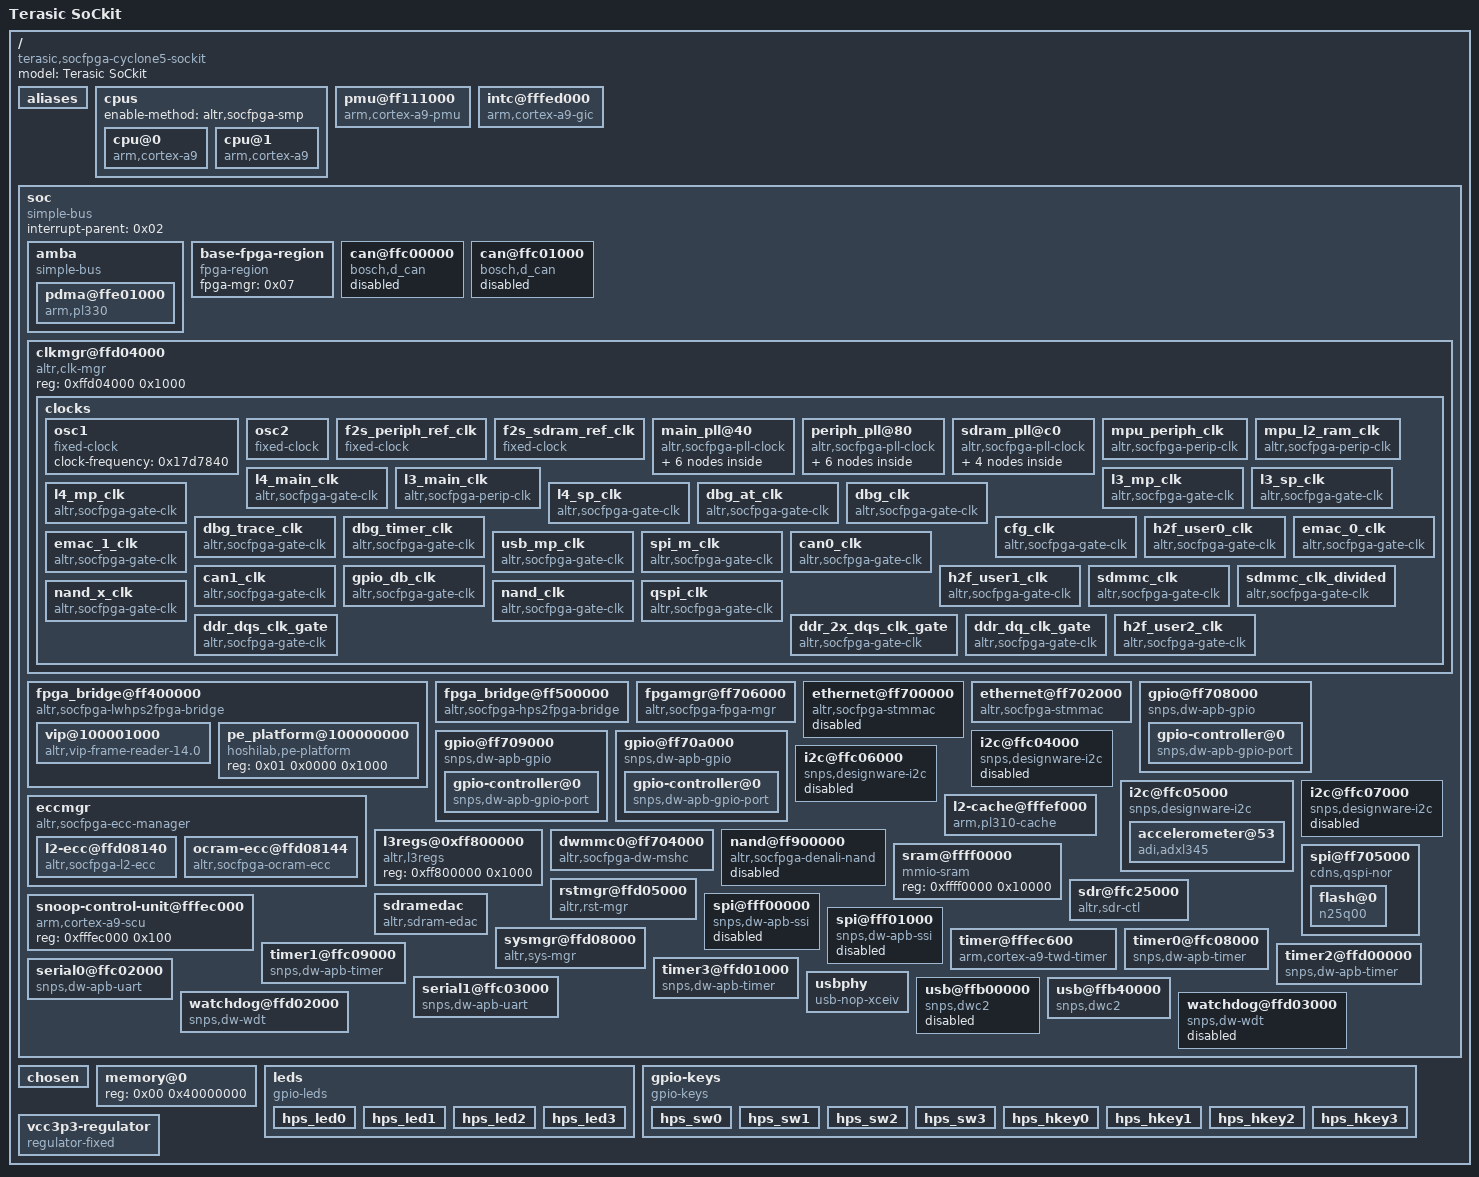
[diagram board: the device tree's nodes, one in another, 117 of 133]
/dts-v1/;

/memreserve/	0x0000000000000000 0x0000000000001000;
/ {
	#address-cells = < 0x01 >;
	#size-cells = < 0x01 >;
	model = "Terasic SoCkit";
	compatible = "terasic,socfpga-cyclone5-sockit\0altr,socfpga-cyclone5\0altr,socfpga";

	aliases {
		ethernet0 = "/soc/ethernet@ff702000";
		ethernet1 = "/soc/ethernet@ff702000";
		serial0 = "/soc/serial0@ffc02000";
		serial1 = "/soc/serial1@ffc03000";
		timer0 = "/soc/timer0@ffc08000";
		timer1 = "/soc/timer1@ffc09000";
		timer2 = "/soc/timer2@ffd00000";
		timer3 = "/soc/timer3@ffd01000";
	};

	cpus {
		#address-cells = < 0x01 >;
		#size-cells = < 0x00 >;
		enable-method = "altr,socfpga-smp";

		cpu@0 {
			compatible = "arm,cortex-a9";
			device_type = "cpu";
			reg = < 0x00 >;
			next-level-cache = < 0x01 >;
			linux,phandle = < 0x03 >;
			phandle = < 0x03 >;
		};

		cpu@1 {
			compatible = "arm,cortex-a9";
			device_type = "cpu";
			reg = < 0x01 >;
			next-level-cache = < 0x01 >;
			linux,phandle = < 0x04 >;
			phandle = < 0x04 >;
		};
	};

	pmu@ff111000 {
		compatible = "arm,cortex-a9-pmu";
		interrupt-parent = < 0x02 >;
		interrupts = < 0x00 0xb0 0x04 0x00 0xb1 0x04 >;
		interrupt-affinity = < 0x03 0x04 >;
		reg = < 0xff111000 0x1000 0xff113000 0x1000 >;
		linux,phandle = < 0x36 >;
		phandle = < 0x36 >;
	};

	intc@fffed000 {
		compatible = "arm,cortex-a9-gic";
		#interrupt-cells = < 0x03 >;
		interrupt-controller;
		reg = < 0xfffed000 0x1000 0xfffec100 0x100 >;
		linux,phandle = < 0x02 >;
		phandle = < 0x02 >;
	};

	soc {
		#address-cells = < 0x01 >;
		#size-cells = < 0x01 >;
		compatible = "simple-bus";
		device_type = "soc";
		interrupt-parent = < 0x02 >;
		ranges;

		amba {
			compatible = "simple-bus";
			#address-cells = < 0x01 >;
			#size-cells = < 0x01 >;
			ranges;

			pdma@ffe01000 {
				compatible = "arm,pl330\0arm,primecell";
				reg = < 0xffe01000 0x1000 >;
				interrupts = < 0x00 0x68 0x04 0x00 0x69 0x04 0x00 0x6a 0x04 0x00 0x6b 0x04 0x00 0x6c 0x04 0x00 0x6d 0x04 0x00 0x6e 0x04 0x00 0x6f 0x04 >;
				#dma-cells = < 0x01 >;
				#dma-channels = < 0x08 >;
				#dma-requests = < 0x20 >;
				clocks = < 0x05 >;
				clock-names = "apb_pclk";
				resets = < 0x06 0x3c >;
				linux,phandle = < 0x32 >;
				phandle = < 0x32 >;
			};
		};

		base-fpga-region {
			compatible = "fpga-region";
			fpga-mgr = < 0x07 >;
			#address-cells = < 0x01 >;
			#size-cells = < 0x01 >;
			linux,phandle = < 0x37 >;
			phandle = < 0x37 >;
		};

		can@ffc00000 {
			compatible = "bosch,d_can";
			reg = < 0xffc00000 0x1000 >;
			interrupts = < 0x00 0x83 0x04 0x00 0x84 0x04 0x00 0x85 0x04 0x00 0x86 0x04 >;
			clocks = < 0x08 >;
			resets = < 0x06 0x37 >;
			status = "disabled";
			linux,phandle = < 0x38 >;
			phandle = < 0x38 >;
		};

		can@ffc01000 {
			compatible = "bosch,d_can";
			reg = < 0xffc01000 0x1000 >;
			interrupts = < 0x00 0x87 0x04 0x00 0x88 0x04 0x00 0x89 0x04 0x00 0x8a 0x04 >;
			clocks = < 0x09 >;
			resets = < 0x06 0x38 >;
			status = "disabled";
			linux,phandle = < 0x39 >;
			phandle = < 0x39 >;
		};

		clkmgr@ffd04000 {
			compatible = "altr,clk-mgr";
			reg = < 0xffd04000 0x1000 >;

			clocks {
				#address-cells = < 0x01 >;
				#size-cells = < 0x00 >;

				osc1 {
					#clock-cells = < 0x00 >;
					compatible = "fixed-clock";
					clock-frequency = < 0x17d7840 >;
					linux,phandle = < 0x0a >;
					phandle = < 0x0a >;
				};

				osc2 {
					#clock-cells = < 0x00 >;
					compatible = "fixed-clock";
					linux,phandle = < 0x0c >;
					phandle = < 0x0c >;
				};

				f2s_periph_ref_clk {
					#clock-cells = < 0x00 >;
					compatible = "fixed-clock";
					linux,phandle = < 0x0d >;
					phandle = < 0x0d >;
				};

				f2s_sdram_ref_clk {
					#clock-cells = < 0x00 >;
					compatible = "fixed-clock";
					linux,phandle = < 0x0f >;
					phandle = < 0x0f >;
				};

				main_pll@40 {
					#address-cells = < 0x01 >;
					#size-cells = < 0x00 >;
					#clock-cells = < 0x00 >;
					compatible = "altr,socfpga-pll-clock";
					clocks = < 0x0a >;
					reg = < 0x40 >;
					linux,phandle = < 0x0b >;
					phandle = < 0x0b >;

					mpuclk@48 {
						#clock-cells = < 0x00 >;
						compatible = "altr,socfpga-perip-clk";
						clocks = < 0x0b >;
						div-reg = < 0xe0 0x00 0x09 >;
						reg = < 0x48 >;
						linux,phandle = < 0x11 >;
						phandle = < 0x11 >;
					};

					mainclk@4c {
						#clock-cells = < 0x00 >;
						compatible = "altr,socfpga-perip-clk";
						clocks = < 0x0b >;
						div-reg = < 0xe4 0x00 0x09 >;
						reg = < 0x4c >;
						linux,phandle = < 0x12 >;
						phandle = < 0x12 >;
					};

					dbg_base_clk@50 {
						#clock-cells = < 0x00 >;
						compatible = "altr,socfpga-perip-clk";
						clocks = < 0x0b 0x0a >;
						div-reg = < 0xe8 0x00 0x09 >;
						reg = < 0x50 >;
						linux,phandle = < 0x15 >;
						phandle = < 0x15 >;
					};

					main_qspi_clk@54 {
						#clock-cells = < 0x00 >;
						compatible = "altr,socfpga-perip-clk";
						clocks = < 0x0b >;
						reg = < 0x54 >;
						linux,phandle = < 0x1e >;
						phandle = < 0x1e >;
					};

					main_nand_sdmmc_clk@58 {
						#clock-cells = < 0x00 >;
						compatible = "altr,socfpga-perip-clk";
						clocks = < 0x0b >;
						reg = < 0x58 >;
						linux,phandle = < 0x1b >;
						phandle = < 0x1b >;
					};

					cfg_h2f_usr0_clk@5c {
						#clock-cells = < 0x00 >;
						compatible = "altr,socfpga-perip-clk";
						clocks = < 0x0b >;
						reg = < 0x5c >;
						linux,phandle = < 0x17 >;
						phandle = < 0x17 >;
					};
				};

				periph_pll@80 {
					#address-cells = < 0x01 >;
					#size-cells = < 0x00 >;
					#clock-cells = < 0x00 >;
					compatible = "altr,socfpga-pll-clock";
					clocks = < 0x0a 0x0c 0x0d >;
					reg = < 0x80 >;
					linux,phandle = < 0x0e >;
					phandle = < 0x0e >;

					emac0_clk@88 {
						#clock-cells = < 0x00 >;
						compatible = "altr,socfpga-perip-clk";
						clocks = < 0x0e >;
						reg = < 0x88 >;
						linux,phandle = < 0x18 >;
						phandle = < 0x18 >;
					};

					emac1_clk@8c {
						#clock-cells = < 0x00 >;
						compatible = "altr,socfpga-perip-clk";
						clocks = < 0x0e >;
						reg = < 0x8c >;
						linux,phandle = < 0x19 >;
						phandle = < 0x19 >;
					};

					per_qsi_clk@90 {
						#clock-cells = < 0x00 >;
						compatible = "altr,socfpga-perip-clk";
						clocks = < 0x0e >;
						reg = < 0x90 >;
						linux,phandle = < 0x1f >;
						phandle = < 0x1f >;
					};

					per_nand_mmc_clk@94 {
						#clock-cells = < 0x00 >;
						compatible = "altr,socfpga-perip-clk";
						clocks = < 0x0e >;
						reg = < 0x94 >;
						linux,phandle = < 0x1c >;
						phandle = < 0x1c >;
					};

					per_base_clk@98 {
						#clock-cells = < 0x00 >;
						compatible = "altr,socfpga-perip-clk";
						clocks = < 0x0e >;
						reg = < 0x98 >;
						linux,phandle = < 0x14 >;
						phandle = < 0x14 >;
					};

					h2f_usr1_clk@9c {
						#clock-cells = < 0x00 >;
						compatible = "altr,socfpga-perip-clk";
						clocks = < 0x0e >;
						reg = < 0x9c >;
						linux,phandle = < 0x1a >;
						phandle = < 0x1a >;
					};
				};

				sdram_pll@c0 {
					#address-cells = < 0x01 >;
					#size-cells = < 0x00 >;
					#clock-cells = < 0x00 >;
					compatible = "altr,socfpga-pll-clock";
					clocks = < 0x0a 0x0c 0x0f >;
					reg = < 0xc0 >;
					linux,phandle = < 0x10 >;
					phandle = < 0x10 >;

					ddr_dqs_clk@c8 {
						#clock-cells = < 0x00 >;
						compatible = "altr,socfpga-perip-clk";
						clocks = < 0x10 >;
						reg = < 0xc8 >;
						linux,phandle = < 0x20 >;
						phandle = < 0x20 >;
					};

					ddr_2x_dqs_clk@cc {
						#clock-cells = < 0x00 >;
						compatible = "altr,socfpga-perip-clk";
						clocks = < 0x10 >;
						reg = < 0xcc >;
						linux,phandle = < 0x21 >;
						phandle = < 0x21 >;
					};

					ddr_dq_clk@d0 {
						#clock-cells = < 0x00 >;
						compatible = "altr,socfpga-perip-clk";
						clocks = < 0x10 >;
						reg = < 0xd0 >;
						linux,phandle = < 0x22 >;
						phandle = < 0x22 >;
					};

					h2f_usr2_clk@d4 {
						#clock-cells = < 0x00 >;
						compatible = "altr,socfpga-perip-clk";
						clocks = < 0x10 >;
						reg = < 0xd4 >;
						linux,phandle = < 0x23 >;
						phandle = < 0x23 >;
					};
				};

				mpu_periph_clk {
					#clock-cells = < 0x00 >;
					compatible = "altr,socfpga-perip-clk";
					clocks = < 0x11 >;
					fixed-divider = < 0x04 >;
					linux,phandle = < 0x31 >;
					phandle = < 0x31 >;
				};

				mpu_l2_ram_clk {
					#clock-cells = < 0x00 >;
					compatible = "altr,socfpga-perip-clk";
					clocks = < 0x11 >;
					fixed-divider = < 0x02 >;
					linux,phandle = < 0x3a >;
					phandle = < 0x3a >;
				};

				l4_main_clk {
					#clock-cells = < 0x00 >;
					compatible = "altr,socfpga-gate-clk";
					clocks = < 0x12 >;
					clk-gate = < 0x60 0x00 >;
					linux,phandle = < 0x05 >;
					phandle = < 0x05 >;
				};

				l3_main_clk {
					#clock-cells = < 0x00 >;
					compatible = "altr,socfpga-perip-clk";
					clocks = < 0x12 >;
					fixed-divider = < 0x01 >;
					linux,phandle = < 0x3b >;
					phandle = < 0x3b >;
				};

				l3_mp_clk {
					#clock-cells = < 0x00 >;
					compatible = "altr,socfpga-gate-clk";
					clocks = < 0x12 >;
					div-reg = < 0x64 0x00 0x02 >;
					clk-gate = < 0x60 0x01 >;
					linux,phandle = < 0x13 >;
					phandle = < 0x13 >;
				};

				l3_sp_clk {
					#clock-cells = < 0x00 >;
					compatible = "altr,socfpga-gate-clk";
					clocks = < 0x13 >;
					div-reg = < 0x64 0x02 0x02 >;
					linux,phandle = < 0x3c >;
					phandle = < 0x3c >;
				};

				l4_mp_clk {
					#clock-cells = < 0x00 >;
					compatible = "altr,socfpga-gate-clk";
					clocks = < 0x12 0x14 >;
					div-reg = < 0x64 0x04 0x03 >;
					clk-gate = < 0x60 0x02 >;
					linux,phandle = < 0x27 >;
					phandle = < 0x27 >;
				};

				l4_sp_clk {
					#clock-cells = < 0x00 >;
					compatible = "altr,socfpga-gate-clk";
					clocks = < 0x12 0x14 >;
					div-reg = < 0x64 0x07 0x03 >;
					clk-gate = < 0x60 0x03 >;
					linux,phandle = < 0x28 >;
					phandle = < 0x28 >;
				};

				dbg_at_clk {
					#clock-cells = < 0x00 >;
					compatible = "altr,socfpga-gate-clk";
					clocks = < 0x15 >;
					div-reg = < 0x68 0x00 0x02 >;
					clk-gate = < 0x60 0x04 >;
					linux,phandle = < 0x16 >;
					phandle = < 0x16 >;
				};

				dbg_clk {
					#clock-cells = < 0x00 >;
					compatible = "altr,socfpga-gate-clk";
					clocks = < 0x16 >;
					div-reg = < 0x68 0x02 0x02 >;
					clk-gate = < 0x60 0x05 >;
					linux,phandle = < 0x3d >;
					phandle = < 0x3d >;
				};

				dbg_trace_clk {
					#clock-cells = < 0x00 >;
					compatible = "altr,socfpga-gate-clk";
					clocks = < 0x15 >;
					div-reg = < 0x6c 0x00 0x03 >;
					clk-gate = < 0x60 0x06 >;
					linux,phandle = < 0x3e >;
					phandle = < 0x3e >;
				};

				dbg_timer_clk {
					#clock-cells = < 0x00 >;
					compatible = "altr,socfpga-gate-clk";
					clocks = < 0x15 >;
					clk-gate = < 0x60 0x07 >;
					linux,phandle = < 0x3f >;
					phandle = < 0x3f >;
				};

				cfg_clk {
					#clock-cells = < 0x00 >;
					compatible = "altr,socfpga-gate-clk";
					clocks = < 0x17 >;
					clk-gate = < 0x60 0x08 >;
					linux,phandle = < 0x40 >;
					phandle = < 0x40 >;
				};

				h2f_user0_clk {
					#clock-cells = < 0x00 >;
					compatible = "altr,socfpga-gate-clk";
					clocks = < 0x17 >;
					clk-gate = < 0x60 0x09 >;
					linux,phandle = < 0x41 >;
					phandle = < 0x41 >;
				};

				emac_0_clk {
					#clock-cells = < 0x00 >;
					compatible = "altr,socfpga-gate-clk";
					clocks = < 0x18 >;
					clk-gate = < 0xa0 0x00 >;
					linux,phandle = < 0x25 >;
					phandle = < 0x25 >;
				};

				emac_1_clk {
					#clock-cells = < 0x00 >;
					compatible = "altr,socfpga-gate-clk";
					clocks = < 0x19 >;
					clk-gate = < 0xa0 0x01 >;
					linux,phandle = < 0x26 >;
					phandle = < 0x26 >;
				};

				usb_mp_clk {
					#clock-cells = < 0x00 >;
					compatible = "altr,socfpga-gate-clk";
					clocks = < 0x14 >;
					clk-gate = < 0xa0 0x02 >;
					div-reg = < 0xa4 0x00 0x03 >;
					linux,phandle = < 0x33 >;
					phandle = < 0x33 >;
				};

				spi_m_clk {
					#clock-cells = < 0x00 >;
					compatible = "altr,socfpga-gate-clk";
					clocks = < 0x14 >;
					clk-gate = < 0xa0 0x03 >;
					div-reg = < 0xa4 0x03 0x03 >;
					linux,phandle = < 0x30 >;
					phandle = < 0x30 >;
				};

				can0_clk {
					#clock-cells = < 0x00 >;
					compatible = "altr,socfpga-gate-clk";
					clocks = < 0x14 >;
					clk-gate = < 0xa0 0x04 >;
					div-reg = < 0xa4 0x06 0x03 >;
					linux,phandle = < 0x08 >;
					phandle = < 0x08 >;
				};

				can1_clk {
					#clock-cells = < 0x00 >;
					compatible = "altr,socfpga-gate-clk";
					clocks = < 0x14 >;
					clk-gate = < 0xa0 0x05 >;
					div-reg = < 0xa4 0x09 0x03 >;
					linux,phandle = < 0x09 >;
					phandle = < 0x09 >;
				};

				gpio_db_clk {
					#clock-cells = < 0x00 >;
					compatible = "altr,socfpga-gate-clk";
					clocks = < 0x14 >;
					clk-gate = < 0xa0 0x06 >;
					div-reg = < 0xa8 0x00 0x18 >;
					linux,phandle = < 0x42 >;
					phandle = < 0x42 >;
				};

				h2f_user1_clk {
					#clock-cells = < 0x00 >;
					compatible = "altr,socfpga-gate-clk";
					clocks = < 0x1a >;
					clk-gate = < 0xa0 0x07 >;
					linux,phandle = < 0x43 >;
					phandle = < 0x43 >;
				};

				sdmmc_clk {
					#clock-cells = < 0x00 >;
					compatible = "altr,socfpga-gate-clk";
					clocks = < 0x0d 0x1b 0x1c >;
					clk-gate = < 0xa0 0x08 >;
					clk-phase = < 0x00 0x87 >;
					linux,phandle = < 0x1d >;
					phandle = < 0x1d >;
				};

				sdmmc_clk_divided {
					#clock-cells = < 0x00 >;
					compatible = "altr,socfpga-gate-clk";
					clocks = < 0x1d >;
					clk-gate = < 0xa0 0x08 >;
					fixed-divider = < 0x04 >;
					linux,phandle = < 0x2b >;
					phandle = < 0x2b >;
				};

				nand_x_clk {
					#clock-cells = < 0x00 >;
					compatible = "altr,socfpga-gate-clk";
					clocks = < 0x0d 0x1b 0x1c >;
					clk-gate = < 0xa0 0x09 >;
					linux,phandle = < 0x2d >;
					phandle = < 0x2d >;
				};

				nand_clk {
					#clock-cells = < 0x00 >;
					compatible = "altr,socfpga-gate-clk";
					clocks = < 0x0d 0x1b 0x1c >;
					clk-gate = < 0xa0 0x0a >;
					fixed-divider = < 0x04 >;
					linux,phandle = < 0x44 >;
					phandle = < 0x44 >;
				};

				qspi_clk {
					#clock-cells = < 0x00 >;
					compatible = "altr,socfpga-gate-clk";
					clocks = < 0x0d 0x1e 0x1f >;
					clk-gate = < 0xa0 0x0b >;
					linux,phandle = < 0x2e >;
					phandle = < 0x2e >;
				};

				ddr_dqs_clk_gate {
					#clock-cells = < 0x00 >;
					compatible = "altr,socfpga-gate-clk";
					clocks = < 0x20 >;
					clk-gate = < 0xd8 0x00 >;
					linux,phandle = < 0x45 >;
					phandle = < 0x45 >;
				};

				ddr_2x_dqs_clk_gate {
					#clock-cells = < 0x00 >;
					compatible = "altr,socfpga-gate-clk";
					clocks = < 0x21 >;
					clk-gate = < 0xd8 0x01 >;
					linux,phandle = < 0x46 >;
					phandle = < 0x46 >;
				};

				ddr_dq_clk_gate {
					#clock-cells = < 0x00 >;
					compatible = "altr,socfpga-gate-clk";
					clocks = < 0x22 >;
					clk-gate = < 0xd8 0x02 >;
					linux,phandle = < 0x47 >;
					phandle = < 0x47 >;
				};

				h2f_user2_clk {
					#clock-cells = < 0x00 >;
					compatible = "altr,socfpga-gate-clk";
					clocks = < 0x23 >;
					clk-gate = < 0xd8 0x03 >;
					linux,phandle = < 0x48 >;
					phandle = < 0x48 >;
				};
			};
		};

		fpga_bridge@ff400000 {
			compatible = "altr,socfpga-lwhps2fpga-bridge";
			reg = < 0xff400000 0x100000 >;
			resets = < 0x06 0x61 >;
			clocks = < 0x05 >;
			linux,phandle = < 0x49 >;
			phandle = < 0x49 >;
			#address-cells = < 0x02 >;
			#size-cells = < 0x01 >;
			ranges = < 0x00000001 0x1000 0xff201000 0x80 >,
				< 0x00000001 0x0000 0xff200000 0x1000 >;

			vip@100001000 {
				compatible = "altr,vip-frame-reader-14.0\0altr,vip-frame-reader-9.1";
				reg = < 0x01 0x1000 0x80 >;
				max-width = < 0x400 >;
				max-height = < 0x300 >;
				bits-per-color = < 0x08 >;
				colors-per-beat = < 0x04 >;
				beats-per-pixel = < 0x01 >;
				mem-word-width = < 0x80 >;
			};
			pe_platform@100000000 {
				compatible = "hoshilab,pe-platform";
				reg = <0x01 0x0000 0x1000>;
			};
		};

		fpga_bridge@ff500000 {
			compatible = "altr,socfpga-hps2fpga-bridge";
			reg = < 0xff500000 0x10000 >;
			resets = < 0x06 0x60 >;
			clocks = < 0x05 >;
			linux,phandle = < 0x4a >;
			phandle = < 0x4a >;
		};

		fpgamgr@ff706000 {
			compatible = "altr,socfpga-fpga-mgr";
			reg = < 0xff706000 0x1000 0xffb90000 0x04 >;
			interrupts = < 0x00 0xaf 0x04 >;
			linux,phandle = < 0x07 >;
			phandle = < 0x07 >;
		};

		ethernet@ff700000 {
			compatible = "altr,socfpga-stmmac\0snps,dwmac-3.70a\0snps,dwmac";
			altr,sysmgr-syscon = < 0x24 0x60 0x00 >;
			reg = < 0xff700000 0x2000 >;
			interrupts = < 0x00 0x73 0x04 >;
			interrupt-names = "macirq";
			mac-address = [ 00 00 00 00 00 00 ];
			clocks = < 0x25 >;
			clock-names = "stmmaceth";
			resets = < 0x06 0x20 >;
			reset-names = "stmmaceth";
			snps,multicast-filter-bins = < 0x100 >;
			snps,perfect-filter-entries = < 0x80 >;
			tx-fifo-depth = < 0x1000 >;
			rx-fifo-depth = < 0x1000 >;
			status = "disabled";
			linux,phandle = < 0x4b >;
			phandle = < 0x4b >;
		};

		ethernet@ff702000 {
			compatible = "altr,socfpga-stmmac\0snps,dwmac-3.70a\0snps,dwmac";
			altr,sysmgr-syscon = < 0x24 0x60 0x02 >;
			reg = < 0xff702000 0x2000 >;
			interrupts = < 0x00 0x78 0x04 >;
			interrupt-names = "macirq";
			mac-address = [ 00 00 00 00 00 00 ];
			clocks = < 0x26 >;
			clock-names = "stmmaceth";
			resets = < 0x06 0x21 >;
			reset-names = "stmmaceth";
			snps,multicast-filter-bins = < 0x100 >;
			snps,perfect-filter-entries = < 0x80 >;
			tx-fifo-depth = < 0x1000 >;
			rx-fifo-depth = < 0x1000 >;
			status = "okay";
			phy-mode = "rgmii";
			rxd0-skew-ps = < 0x00 >;
			rxd1-skew-ps = < 0x00 >;
			rxd2-skew-ps = < 0x00 >;
			rxd3-skew-ps = < 0x00 >;
			txen-skew-ps = < 0x00 >;
			txc-skew-ps = < 0xa28 >;
			rxdv-skew-ps = < 0x00 >;
			rxc-skew-ps = < 0x7d0 >;
			linux,phandle = < 0x4c >;
			phandle = < 0x4c >;
		};

		gpio@ff708000 {
			#address-cells = < 0x01 >;
			#size-cells = < 0x00 >;
			compatible = "snps,dw-apb-gpio";
			reg = < 0xff708000 0x1000 >;
			clocks = < 0x27 >;
			resets = < 0x06 0x39 >;
			status = "okay";
			linux,phandle = < 0x4d >;
			phandle = < 0x4d >;

			gpio-controller@0 {
				compatible = "snps,dw-apb-gpio-port";
				gpio-controller;
				#gpio-cells = < 0x02 >;
				snps,nr-gpios = < 0x1d >;
				reg = < 0x00 >;
				interrupt-controller;
				#interrupt-cells = < 0x02 >;
				interrupts = < 0x00 0xa4 0x04 >;
				linux,phandle = < 0x4e >;
				phandle = < 0x4e >;
			};
		};

		gpio@ff709000 {
			#address-cells = < 0x01 >;
			#size-cells = < 0x00 >;
			compatible = "snps,dw-apb-gpio";
			reg = < 0xff709000 0x1000 >;
			clocks = < 0x27 >;
			resets = < 0x06 0x3a >;
			status = "okay";
			linux,phandle = < 0x4f >;
			phandle = < 0x4f >;

			gpio-controller@0 {
				compatible = "snps,dw-apb-gpio-port";
				gpio-controller;
				#gpio-cells = < 0x02 >;
				snps,nr-gpios = < 0x1d >;
				reg = < 0x00 >;
				interrupt-controller;
				#interrupt-cells = < 0x02 >;
				interrupts = < 0x00 0xa5 0x04 >;
				linux,phandle = < 0x35 >;
				phandle = < 0x35 >;
			};
		};

		gpio@ff70a000 {
			#address-cells = < 0x01 >;
			#size-cells = < 0x00 >;
			compatible = "snps,dw-apb-gpio";
			reg = < 0xff70a000 0x1000 >;
			clocks = < 0x27 >;
			resets = < 0x06 0x3b >;
			status = "okay";
			linux,phandle = < 0x50 >;
			phandle = < 0x50 >;

			gpio-controller@0 {
				compatible = "snps,dw-apb-gpio-port";
				gpio-controller;
				#gpio-cells = < 0x02 >;
				snps,nr-gpios = < 0x1b >;
				reg = < 0x00 >;
				interrupt-controller;
				#interrupt-cells = < 0x02 >;
				interrupts = < 0x00 0xa6 0x04 >;
				linux,phandle = < 0x29 >;
				phandle = < 0x29 >;
			};
		};

		i2c@ffc04000 {
			#address-cells = < 0x01 >;
			#size-cells = < 0x00 >;
			compatible = "snps,designware-i2c";
			reg = < 0xffc04000 0x1000 >;
			clocks = < 0x28 >;
			interrupts = < 0x00 0x9e 0x04 >;
			status = "disabled";
			linux,phandle = < 0x51 >;
			phandle = < 0x51 >;
		};

		i2c@ffc05000 {
			#address-cells = < 0x01 >;
			#size-cells = < 0x00 >;
			compatible = "snps,designware-i2c";
			reg = < 0xffc05000 0x1000 >;
			clocks = < 0x28 >;
			interrupts = < 0x00 0x9f 0x04 >;
			status = "okay";
			linux,phandle = < 0x52 >;
			phandle = < 0x52 >;

			accelerometer@53 {
				compatible = "adi,adxl345";
				reg = < 0x53 >;
				interrupt-parent = < 0x29 >;
				interrupts = < 0x03 0x02 >;
				linux,phandle = < 0x53 >;
				phandle = < 0x53 >;
			};
		};

		i2c@ffc06000 {
			#address-cells = < 0x01 >;
			#size-cells = < 0x00 >;
			compatible = "snps,designware-i2c";
			reg = < 0xffc06000 0x1000 >;
			clocks = < 0x28 >;
			interrupts = < 0x00 0xa0 0x04 >;
			status = "disabled";
			linux,phandle = < 0x54 >;
			phandle = < 0x54 >;
		};

		i2c@ffc07000 {
			#address-cells = < 0x01 >;
			#size-cells = < 0x00 >;
			compatible = "snps,designware-i2c";
			reg = < 0xffc07000 0x1000 >;
			clocks = < 0x28 >;
			interrupts = < 0x00 0xa1 0x04 >;
			status = "disabled";
			linux,phandle = < 0x55 >;
			phandle = < 0x55 >;
		};

		eccmgr {
			compatible = "altr,socfpga-ecc-manager";
			#address-cells = < 0x01 >;
			#size-cells = < 0x01 >;
			ranges;
			linux,phandle = < 0x56 >;
			phandle = < 0x56 >;

			l2-ecc@ffd08140 {
				compatible = "altr,socfpga-l2-ecc";
				reg = < 0xffd08140 0x04 >;
				interrupts = < 0x00 0x24 0x01 0x00 0x25 0x01 >;
			};

			ocram-ecc@ffd08144 {
				compatible = "altr,socfpga-ocram-ecc";
				reg = < 0xffd08144 0x04 >;
				iram = < 0x2a >;
				interrupts = < 0x00 0xb2 0x01 0x00 0xb3 0x01 >;
			};
		};

		l2-cache@fffef000 {
			compatible = "arm,pl310-cache";
			reg = < 0xfffef000 0x1000 >;
			interrupts = < 0x00 0x26 0x04 >;
			cache-unified;
			cache-level = < 0x02 >;
			arm,tag-latency = < 0x01 0x01 0x01 >;
			arm,data-latency = < 0x02 0x01 0x01 >;
			prefetch-data = < 0x01 >;
			prefetch-instr = < 0x01 >;
			arm,shared-override;
			arm,double-linefill = < 0x01 >;
			arm,double-linefill-incr = < 0x00 >;
			arm,double-linefill-wrap = < 0x01 >;
			arm,prefetch-drop = < 0x00 >;
			arm,prefetch-offset = < 0x07 >;
			linux,phandle = < 0x01 >;
			phandle = < 0x01 >;
		};

		l3regs@0xff800000 {
			compatible = "altr,l3regs\0syscon";
			reg = < 0xff800000 0x1000 >;
		};

		dwmmc0@ff704000 {
			compatible = "altr,socfpga-dw-mshc";
			reg = < 0xff704000 0x1000 >;
			interrupts = < 0x00 0x8b 0x04 >;
			fifo-depth = < 0x400 >;
			#address-cells = < 0x01 >;
			#size-cells = < 0x00 >;
			clocks = < 0x27 0x2b >;
			clock-names = "biu\0ciu";
			resets = < 0x06 0x36 >;
			status = "okay";
			broken-cd;
			bus-width = < 0x04 >;
			cap-mmc-highspeed;
			cap-sd-highspeed;
			vmmc-supply = < 0x2c >;
			vqmmc-supply = < 0x2c >;
			linux,phandle = < 0x57 >;
			phandle = < 0x57 >;
		};

		nand@ff900000 {
			#address-cells = < 0x01 >;
			#size-cells = < 0x01 >;
			compatible = "altr,socfpga-denali-nand";
			reg = < 0xff900000 0x100000 0xffb80000 0x10000 >;
			reg-names = "nand_data\0denali_reg";
			interrupts = < 0x00 0x90 0x04 >;
			dma-mask = < 0xffffffff >;
			clocks = < 0x2d >;
			resets = < 0x06 0x24 >;
			status = "disabled";
			linux,phandle = < 0x58 >;
			phandle = < 0x58 >;
		};

		sram@ffff0000 {
			compatible = "mmio-sram";
			reg = < 0xffff0000 0x10000 >;
			linux,phandle = < 0x2a >;
			phandle = < 0x2a >;
		};

		spi@ff705000 {
			compatible = "cdns,qspi-nor";
			#address-cells = < 0x01 >;
			#size-cells = < 0x00 >;
			reg = < 0xff705000 0x1000 0xffa00000 0x1000 >;
			interrupts = < 0x00 0x97 0x04 >;
			cdns,fifo-depth = < 0x80 >;
			cdns,fifo-width = < 0x04 >;
			cdns,trigger-address = < 0x00 >;
			clocks = < 0x2e >;
			resets = < 0x06 0x25 >;
			status = "okay";
			linux,phandle = < 0x59 >;
			phandle = < 0x59 >;

			flash@0 {
				#address-cells = < 0x01 >;
				#size-cells = < 0x01 >;
				compatible = "n25q00";
				reg = < 0x00 >;
				spi-max-frequency = < 0x5f5e100 >;
				m25p,fast-read;
				cdns,page-size = < 0x100 >;
				cdns,block-size = < 0x10 >;
				cdns,read-delay = < 0x04 >;
				cdns,tshsl-ns = < 0x32 >;
				cdns,tsd2d-ns = < 0x32 >;
				cdns,tchsh-ns = < 0x04 >;
				cdns,tslch-ns = < 0x04 >;
				linux,phandle = < 0x5a >;
				phandle = < 0x5a >;
			};
		};

		rstmgr@ffd05000 {
			#reset-cells = < 0x01 >;
			compatible = "altr,rst-mgr";
			reg = < 0xffd05000 0x1000 >;
			altr,modrst-offset = < 0x10 >;
			linux,phandle = < 0x06 >;
			phandle = < 0x06 >;
		};

		snoop-control-unit@fffec000 {
			compatible = "arm,cortex-a9-scu";
			reg = < 0xfffec000 0x100 >;
			linux,phandle = < 0x5b >;
			phandle = < 0x5b >;
		};

		sdr@ffc25000 {
			compatible = "altr,sdr-ctl\0syscon";
			reg = < 0xffc25000 0x1000 >;
			resets = < 0x06 0x3d >;
			linux,phandle = < 0x2f >;
			phandle = < 0x2f >;
		};

		sdramedac {
			compatible = "altr,sdram-edac";
			altr,sdr-syscon = < 0x2f >;
			interrupts = < 0x00 0x27 0x04 >;
		};

		spi@fff00000 {
			compatible = "snps,dw-apb-ssi";
			#address-cells = < 0x01 >;
			#size-cells = < 0x00 >;
			reg = < 0xfff00000 0x1000 >;
			interrupts = < 0x00 0x9a 0x04 >;
			num-cs = < 0x04 >;
			clocks = < 0x30 >;
			resets = < 0x06 0x32 >;
			status = "disabled";
			linux,phandle = < 0x5c >;
			phandle = < 0x5c >;
		};

		spi@fff01000 {
			compatible = "snps,dw-apb-ssi";
			#address-cells = < 0x01 >;
			#size-cells = < 0x00 >;
			reg = < 0xfff01000 0x1000 >;
			interrupts = < 0x00 0x9b 0x04 >;
			num-cs = < 0x04 >;
			clocks = < 0x30 >;
			resets = < 0x06 0x33 >;
			status = "disabled";
			linux,phandle = < 0x5d >;
			phandle = < 0x5d >;
		};

		sysmgr@ffd08000 {
			compatible = "altr,sys-mgr\0syscon";
			reg = < 0xffd08000 0x4000 >;
			cpu1-start-addr = < 0xffd080c4 >;
			linux,phandle = < 0x24 >;
			phandle = < 0x24 >;
		};

		timer@fffec600 {
			compatible = "arm,cortex-a9-twd-timer";
			reg = < 0xfffec600 0x100 >;
			interrupts = < 0x01 0x0d 0xf01 >;
			clocks = < 0x31 >;
		};

		timer0@ffc08000 {
			compatible = "snps,dw-apb-timer";
			interrupts = < 0x00 0xa7 0x04 >;
			reg = < 0xffc08000 0x1000 >;
			clocks = < 0x28 >;
			clock-names = "timer";
			resets = < 0x06 0x2a >;
			reset-names = "timer";
			linux,phandle = < 0x5e >;
			phandle = < 0x5e >;
		};

		timer1@ffc09000 {
			compatible = "snps,dw-apb-timer";
			interrupts = < 0x00 0xa8 0x04 >;
			reg = < 0xffc09000 0x1000 >;
			clocks = < 0x28 >;
			clock-names = "timer";
			resets = < 0x06 0x2b >;
			reset-names = "timer";
			linux,phandle = < 0x5f >;
			phandle = < 0x5f >;
		};

		timer2@ffd00000 {
			compatible = "snps,dw-apb-timer";
			interrupts = < 0x00 0xa9 0x04 >;
			reg = < 0xffd00000 0x1000 >;
			clocks = < 0x0a >;
			clock-names = "timer";
			resets = < 0x06 0x28 >;
			reset-names = "timer";
			linux,phandle = < 0x60 >;
			phandle = < 0x60 >;
		};

		timer3@ffd01000 {
			compatible = "snps,dw-apb-timer";
			interrupts = < 0x00 0xaa 0x04 >;
			reg = < 0xffd01000 0x1000 >;
			clocks = < 0x0a >;
			clock-names = "timer";
			resets = < 0x06 0x29 >;
			reset-names = "timer";
			linux,phandle = < 0x61 >;
			phandle = < 0x61 >;
		};

		serial0@ffc02000 {
			compatible = "snps,dw-apb-uart";
			reg = < 0xffc02000 0x1000 >;
			interrupts = < 0x00 0xa2 0x04 >;
			reg-shift = < 0x02 >;
			reg-io-width = < 0x04 >;
			clocks = < 0x28 >;
			dmas = < 0x32 0x1c 0x32 0x1d >;
			dma-names = "tx\0rx";
			resets = < 0x06 0x30 >;
			linux,phandle = < 0x62 >;
			phandle = < 0x62 >;
		};

		serial1@ffc03000 {
			compatible = "snps,dw-apb-uart";
			reg = < 0xffc03000 0x1000 >;
			interrupts = < 0x00 0xa3 0x04 >;
			reg-shift = < 0x02 >;
			reg-io-width = < 0x04 >;
			clocks = < 0x28 >;
			dmas = < 0x32 0x1e 0x32 0x1f >;
			dma-names = "tx\0rx";
			resets = < 0x06 0x31 >;
			linux,phandle = < 0x63 >;
			phandle = < 0x63 >;
		};

		usbphy {
			#phy-cells = < 0x00 >;
			compatible = "usb-nop-xceiv";
			status = "okay";
			linux,phandle = < 0x34 >;
			phandle = < 0x34 >;
		};

		usb@ffb00000 {
			compatible = "snps,dwc2";
			reg = < 0xffb00000 0xffff >;
			interrupts = < 0x00 0x7d 0x04 >;
			clocks = < 0x33 >;
			clock-names = "otg";
			resets = < 0x06 0x22 >;
			reset-names = "dwc2";
			phys = < 0x34 >;
			phy-names = "usb2-phy";
			status = "disabled";
			linux,phandle = < 0x64 >;
			phandle = < 0x64 >;
		};

		usb@ffb40000 {
			compatible = "snps,dwc2";
			reg = < 0xffb40000 0xffff >;
			interrupts = < 0x00 0x80 0x04 >;
			clocks = < 0x33 >;
			clock-names = "otg";
			resets = < 0x06 0x23 >;
			reset-names = "dwc2";
			phys = < 0x34 >;
			phy-names = "usb2-phy";
			status = "okay";
			linux,phandle = < 0x65 >;
			phandle = < 0x65 >;
		};

		watchdog@ffd02000 {
			compatible = "snps,dw-wdt";
			reg = < 0xffd02000 0x1000 >;
			interrupts = < 0x00 0xab 0x04 >;
			clocks = < 0x0a >;
			resets = < 0x06 0x26 >;
			status = "okay";
			linux,phandle = < 0x66 >;
			phandle = < 0x66 >;
		};

		watchdog@ffd03000 {
			compatible = "snps,dw-wdt";
			reg = < 0xffd03000 0x1000 >;
			interrupts = < 0x00 0xac 0x04 >;
			clocks = < 0x0a >;
			resets = < 0x06 0x27 >;
			status = "disabled";
			linux,phandle = < 0x67 >;
			phandle = < 0x67 >;
		};
	};

	chosen {
		bootargs = "earlyprintk";
		stdout-path = "serial0:115200n8";
	};

	memory@0 {
		device_type = "memory";
		reg = < 0x00 0x40000000 >;
	};

	leds {
		compatible = "gpio-leds";

		hps_led0 {
			label = "hps:blue:led0";
			gpios = < 0x35 0x18 0x00 >;
			linux,default-trigger = "heartbeat";
		};

		hps_led1 {
			label = "hps:blue:led1";
			gpios = < 0x35 0x19 0x00 >;
			linux,default-trigger = "heartbeat";
		};

		hps_led2 {
			label = "hps:blue:led2";
			gpios = < 0x35 0x1a 0x00 >;
			linux,default-trigger = "heartbeat";
		};

		hps_led3 {
			label = "hps:blue:led3";
			gpios = < 0x35 0x1b 0x00 >;
			linux,default-trigger = "heartbeat";
		};
	};

	gpio-keys {
		compatible = "gpio-keys";

		hps_sw0 {
			label = "hps_sw0";
			gpios = < 0x29 0x14 0x00 >;
			linux,input-type = < 0x05 >;
			linux,code = < 0x00 >;
		};

		hps_sw1 {
			label = "hps_sw1";
			gpios = < 0x29 0x13 0x00 >;
			linux,input-type = < 0x05 >;
			linux,code = < 0x05 >;
		};

		hps_sw2 {
			label = "hps_sw2";
			gpios = < 0x29 0x12 0x00 >;
			linux,input-type = < 0x05 >;
			linux,code = < 0x0a >;
		};

		hps_sw3 {
			label = "hps_sw3";
			gpios = < 0x29 0x11 0x00 >;
			linux,input-type = < 0x05 >;
			linux,code = < 0x0c >;
		};

		hps_hkey0 {
			label = "hps_hkey0";
			gpios = < 0x29 0x15 0x01 >;
			linux,code = < 0xbb >;
		};

		hps_hkey1 {
			label = "hps_hkey1";
			gpios = < 0x29 0x16 0x01 >;
			linux,code = < 0xbc >;
		};

		hps_hkey2 {
			label = "hps_hkey2";
			gpios = < 0x29 0x17 0x01 >;
			linux,code = < 0xbd >;
		};

		hps_hkey3 {
			label = "hps_hkey3";
			gpios = < 0x29 0x18 0x01 >;
			linux,code = < 0xbe >;
		};
	};

	vcc3p3-regulator {
		compatible = "regulator-fixed";
		regulator-name = "VCC3P3";
		regulator-min-microvolt = < 0x325aa0 >;
		regulator-max-microvolt = < 0x325aa0 >;
		linux,phandle = < 0x2c >;
		phandle = < 0x2c >;
	};

	__symbols__ {
		cpu0 = "/cpus/cpu@0";
		cpu1 = "/cpus/cpu@1";
		pmu = "/pmu@ff111000";
		intc = "/intc@fffed000";
		pdma = "/soc/amba/pdma@ffe01000";
		base_fpga_region = "/soc/base-fpga-region";
		can0 = "/soc/can@ffc00000";
		can1 = "/soc/can@ffc01000";
		osc1 = "/soc/clkmgr@ffd04000/clocks/osc1";
		osc2 = "/soc/clkmgr@ffd04000/clocks/osc2";
		f2s_periph_ref_clk = "/soc/clkmgr@ffd04000/clocks/f2s_periph_ref_clk";
		f2s_sdram_ref_clk = "/soc/clkmgr@ffd04000/clocks/f2s_sdram_ref_clk";
		main_pll = "/soc/clkmgr@ffd04000/clocks/main_pll@40";
		mpuclk = "/soc/clkmgr@ffd04000/clocks/main_pll@40/mpuclk@48";
		mainclk = "/soc/clkmgr@ffd04000/clocks/main_pll@40/mainclk@4c";
		dbg_base_clk = "/soc/clkmgr@ffd04000/clocks/main_pll@40/dbg_base_clk@50";
		main_qspi_clk = "/soc/clkmgr@ffd04000/clocks/main_pll@40/main_qspi_clk@54";
		main_nand_sdmmc_clk = "/soc/clkmgr@ffd04000/clocks/main_pll@40/main_nand_sdmmc_clk@58";
		cfg_h2f_usr0_clk = "/soc/clkmgr@ffd04000/clocks/main_pll@40/cfg_h2f_usr0_clk@5c";
		periph_pll = "/soc/clkmgr@ffd04000/clocks/periph_pll@80";
		emac0_clk = "/soc/clkmgr@ffd04000/clocks/periph_pll@80/emac0_clk@88";
		emac1_clk = "/soc/clkmgr@ffd04000/clocks/periph_pll@80/emac1_clk@8c";
		per_qspi_clk = "/soc/clkmgr@ffd04000/clocks/periph_pll@80/per_qsi_clk@90";
		per_nand_mmc_clk = "/soc/clkmgr@ffd04000/clocks/periph_pll@80/per_nand_mmc_clk@94";
		per_base_clk = "/soc/clkmgr@ffd04000/clocks/periph_pll@80/per_base_clk@98";
		h2f_usr1_clk = "/soc/clkmgr@ffd04000/clocks/periph_pll@80/h2f_usr1_clk@9c";
		sdram_pll = "/soc/clkmgr@ffd04000/clocks/sdram_pll@c0";
		ddr_dqs_clk = "/soc/clkmgr@ffd04000/clocks/sdram_pll@c0/ddr_dqs_clk@c8";
		ddr_2x_dqs_clk = "/soc/clkmgr@ffd04000/clocks/sdram_pll@c0/ddr_2x_dqs_clk@cc";
		ddr_dq_clk = "/soc/clkmgr@ffd04000/clocks/sdram_pll@c0/ddr_dq_clk@d0";
		h2f_usr2_clk = "/soc/clkmgr@ffd04000/clocks/sdram_pll@c0/h2f_usr2_clk@d4";
		mpu_periph_clk = "/soc/clkmgr@ffd04000/clocks/mpu_periph_clk";
		mpu_l2_ram_clk = "/soc/clkmgr@ffd04000/clocks/mpu_l2_ram_clk";
		l4_main_clk = "/soc/clkmgr@ffd04000/clocks/l4_main_clk";
		l3_main_clk = "/soc/clkmgr@ffd04000/clocks/l3_main_clk";
		l3_mp_clk = "/soc/clkmgr@ffd04000/clocks/l3_mp_clk";
		l3_sp_clk = "/soc/clkmgr@ffd04000/clocks/l3_sp_clk";
		l4_mp_clk = "/soc/clkmgr@ffd04000/clocks/l4_mp_clk";
		l4_sp_clk = "/soc/clkmgr@ffd04000/clocks/l4_sp_clk";
		dbg_at_clk = "/soc/clkmgr@ffd04000/clocks/dbg_at_clk";
		dbg_clk = "/soc/clkmgr@ffd04000/clocks/dbg_clk";
		dbg_trace_clk = "/soc/clkmgr@ffd04000/clocks/dbg_trace_clk";
		dbg_timer_clk = "/soc/clkmgr@ffd04000/clocks/dbg_timer_clk";
		cfg_clk = "/soc/clkmgr@ffd04000/clocks/cfg_clk";
		h2f_user0_clk = "/soc/clkmgr@ffd04000/clocks/h2f_user0_clk";
		emac_0_clk = "/soc/clkmgr@ffd04000/clocks/emac_0_clk";
		emac_1_clk = "/soc/clkmgr@ffd04000/clocks/emac_1_clk";
		usb_mp_clk = "/soc/clkmgr@ffd04000/clocks/usb_mp_clk";
		spi_m_clk = "/soc/clkmgr@ffd04000/clocks/spi_m_clk";
		can0_clk = "/soc/clkmgr@ffd04000/clocks/can0_clk";
		can1_clk = "/soc/clkmgr@ffd04000/clocks/can1_clk";
		gpio_db_clk = "/soc/clkmgr@ffd04000/clocks/gpio_db_clk";
		h2f_user1_clk = "/soc/clkmgr@ffd04000/clocks/h2f_user1_clk";
		sdmmc_clk = "/soc/clkmgr@ffd04000/clocks/sdmmc_clk";
		sdmmc_clk_divided = "/soc/clkmgr@ffd04000/clocks/sdmmc_clk_divided";
		nand_x_clk = "/soc/clkmgr@ffd04000/clocks/nand_x_clk";
		nand_clk = "/soc/clkmgr@ffd04000/clocks/nand_clk";
		qspi_clk = "/soc/clkmgr@ffd04000/clocks/qspi_clk";
		ddr_dqs_clk_gate = "/soc/clkmgr@ffd04000/clocks/ddr_dqs_clk_gate";
		ddr_2x_dqs_clk_gate = "/soc/clkmgr@ffd04000/clocks/ddr_2x_dqs_clk_gate";
		ddr_dq_clk_gate = "/soc/clkmgr@ffd04000/clocks/ddr_dq_clk_gate";
		h2f_user2_clk = "/soc/clkmgr@ffd04000/clocks/h2f_user2_clk";
		fpga_bridge0 = "/soc/fpga_bridge@ff400000";
		fpga_bridge1 = "/soc/fpga_bridge@ff500000";
		fpgamgr0 = "/soc/fpgamgr@ff706000";
		gmac0 = "/soc/ethernet@ff700000";
		gmac1 = "/soc/ethernet@ff702000";
		gpio0 = "/soc/gpio@ff708000";
		porta = "/soc/gpio@ff708000/gpio-controller@0";
		gpio1 = "/soc/gpio@ff709000";
		portb = "/soc/gpio@ff709000/gpio-controller@0";
		gpio2 = "/soc/gpio@ff70a000";
		portc = "/soc/gpio@ff70a000/gpio-controller@0";
		i2c0 = "/soc/i2c@ffc04000";
		i2c1 = "/soc/i2c@ffc05000";
		accel1 = "/soc/i2c@ffc05000/accelerometer@53";
		i2c2 = "/soc/i2c@ffc06000";
		i2c3 = "/soc/i2c@ffc07000";
		eccmgr = "/soc/eccmgr";
		L2 = "/soc/l2-cache@fffef000";
		mmc0 = "/soc/dwmmc0@ff704000";
		mmc = "/soc/dwmmc0@ff704000";
		nand0 = "/soc/nand@ff900000";
		ocram = "/soc/sram@ffff0000";
		qspi = "/soc/spi@ff705000";
		flash = "/soc/spi@ff705000/flash@0";
		rst = "/soc/rstmgr@ffd05000";
		scu = "/soc/snoop-control-unit@fffec000";
		sdr = "/soc/sdr@ffc25000";
		spi0 = "/soc/spi@fff00000";
		spi1 = "/soc/spi@fff01000";
		sysmgr = "/soc/sysmgr@ffd08000";
		timer0 = "/soc/timer0@ffc08000";
		timer1 = "/soc/timer1@ffc09000";
		timer2 = "/soc/timer2@ffd00000";
		timer3 = "/soc/timer3@ffd01000";
		uart0 = "/soc/serial0@ffc02000";
		uart1 = "/soc/serial1@ffc03000";
		usbphy0 = "/soc/usbphy";
		usb0 = "/soc/usb@ffb00000";
		usb1 = "/soc/usb@ffb40000";
		watchdog0 = "/soc/watchdog@ffd02000";
		watchdog1 = "/soc/watchdog@ffd03000";
		regulator_3_3v = "/vcc3p3-regulator";
	};
};
